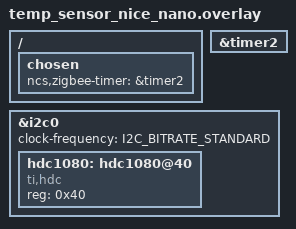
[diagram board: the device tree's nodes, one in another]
/ {
	chosen {
		ncs,zigbee-timer = &timer2;
	};
};

&timer2 {
	status = "okay";
};

&i2c0 {
	status = "okay";
	clock-frequency = <I2C_BITRATE_STANDARD>;

	hdc1080: hdc1080@40 {
		compatible = "ti,hdc";
		reg = <0x40>;
	};
};
